# SYSCTRL_PADCONF_CORE register map
Vendor: Texas Instruments
Registers are 32-bit, access per field, reset 0x10F010F unless marked. A register's access mark holds for its fields unless they carry their own. Offsets are as the file gives them; [hi:lo] are bit positions; {n}, {i} and the like mark numbered series; 'fields as' and 'values as' point back to an identical list.

## SYSCTRL_PADCONF_CORE (part 4 of 10)
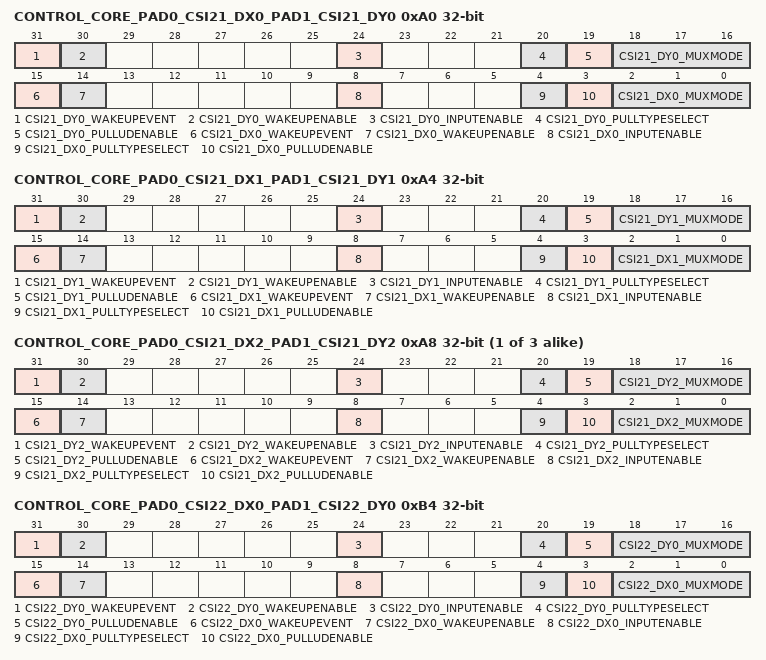
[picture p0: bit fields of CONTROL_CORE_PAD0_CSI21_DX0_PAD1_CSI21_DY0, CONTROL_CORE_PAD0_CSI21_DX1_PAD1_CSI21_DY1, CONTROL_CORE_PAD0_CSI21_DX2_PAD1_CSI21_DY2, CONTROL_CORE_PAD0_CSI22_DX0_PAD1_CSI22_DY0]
0xA0 CONTROL_CORE_PAD0_CSI21_DX0_PAD1_CSI21_DY0 — Register control for Pads csi21_dx0 and csi21_dy0 Access conditions. Read: unrestricted, Write: unrestricted
  [31] CSI21_DY0_WAKEUPEVENT ro — Pad_x wake-up event status latched in the IO
    0=CSI21_DY0_WAKEUPEVENT_0_r (No wake-up event occurred); 1=CSI21_DY0_WAKEUPEVENT_1_r (A wake-up event occurred)
  [30] CSI21_DY0_WAKEUPENABLE rw — Input pad wake-up enable (and OFF mode input enable value)
    0=wake-up detection is disabled; 1=wake-up detection is enabled
  [24] CSI21_DY0_INPUTENABLE rw — Input enable value for pad csi21_dy0
    0=Input buffer of I/O cell is disabled; 1=Input buffer of I/O cell is enabled
  [20] CSI21_DY0_PULLTYPESELECT rw — pullup/down selection for pad csi21_dy0
    0=pulldown selected; 1=pullup selected
  [19] CSI21_DY0_PULLUDENABLE rw — pullup/down enable for pad csi21_dy0
    0=pullup/down disabled; 1=pullup/down enabled
  [18:16] CSI21_DY0_MUXMODE rw — Functional multiplexing selection for pad csi21_dy0
    0=Select csi21_dy0; 3=Select gpi_68; 7=Select safe_mode
  [15] CSI21_DX0_WAKEUPEVENT ro — Pad_x wake-up event status latched in the IO
    0=CSI21_DX0_WAKEUPEVENT_0_r (No wake-up event occurred); 1=CSI21_DX0_WAKEUPEVENT_1_r (A wake-up event occurred)
  [14] CSI21_DX0_WAKEUPENABLE rw — Input pad wake-up enable (and OFF mode input enable value)
    values as CSI21_DY0_WAKEUPENABLE
  [8] CSI21_DX0_INPUTENABLE rw — Input enable value for pad csi21_dx0
    values as CSI21_DY0_INPUTENABLE
  [4] CSI21_DX0_PULLTYPESELECT rw — pullup/down selection for pad csi21_dx0
    0=pulldown selected; 1=pullup selected
  [3] CSI21_DX0_PULLUDENABLE rw — pullup/down enable for pad csi21_dx0
    0=pullup/down disabled; 1=pullup/down enabled
  [2:0] CSI21_DX0_MUXMODE rw — Functional multiplexing selection for pad csi21_dx0
    0=Select csi21_dx0; 3=Select gpi_67; 7=Select safe_mode
0xA4 CONTROL_CORE_PAD0_CSI21_DX1_PAD1_CSI21_DY1 — Register control for Pads csi21_dx1 and csi21_dy1 Access conditions. Read: unrestricted, Write: unrestricted
  [31] CSI21_DY1_WAKEUPEVENT ro — Pad_x wake-up event status latched in the IO
    0=CSI21_DY1_WAKEUPEVENT_0_r (No wake-up event occurred); 1=CSI21_DY1_WAKEUPEVENT_1_r (A wake-up event occurred)
  [30] CSI21_DY1_WAKEUPENABLE rw — Input pad wake-up enable (and OFF mode input enable value)
    values as CONTROL_CORE_PAD0_CSI21_DX0_PAD1_CSI21_DY0.CSI21_DY0_WAKEUPENABLE
  [24] CSI21_DY1_INPUTENABLE rw — Input enable value for pad csi21_dy1
    values as CONTROL_CORE_PAD0_CSI21_DX0_PAD1_CSI21_DY0.CSI21_DY0_INPUTENABLE
  [20] CSI21_DY1_PULLTYPESELECT rw — pullup/down selection for pad csi21_dy1
    0=pulldown selected; 1=pullup selected
  [19] CSI21_DY1_PULLUDENABLE rw — pullup/down enable for pad csi21_dy1
    0=pullup/down disabled; 1=pullup/down enabled
  [18:16] CSI21_DY1_MUXMODE rw — Functional multiplexing selection for pad csi21_dy1
    0=Select csi21_dy1; 3=Select gpi_70; 7=Select safe_mode
  [15] CSI21_DX1_WAKEUPEVENT ro — Pad_x wake-up event status latched in the IO
    0=CSI21_DX1_WAKEUPEVENT_0_r (No wake-up event occurred); 1=CSI21_DX1_WAKEUPEVENT_1_r (A wake-up event occurred)
  [14] CSI21_DX1_WAKEUPENABLE rw — Input pad wake-up enable (and OFF mode input enable value)
    values as CONTROL_CORE_PAD0_CSI21_DX0_PAD1_CSI21_DY0.CSI21_DY0_WAKEUPENABLE
  [8] CSI21_DX1_INPUTENABLE rw — Input enable value for pad csi21_dx1
    values as CONTROL_CORE_PAD0_CSI21_DX0_PAD1_CSI21_DY0.CSI21_DY0_INPUTENABLE
  [4] CSI21_DX1_PULLTYPESELECT rw — pullup/down selection for pad csi21_dx1
    0=pulldown selected; 1=pullup selected
  [3] CSI21_DX1_PULLUDENABLE rw — pullup/down enable for pad csi21_dx1
    0=pullup/down disabled; 1=pullup/down enabled
  [2:0] CSI21_DX1_MUXMODE rw — Functional multiplexing selection for pad csi21_dx1
    0=Select csi21_dx1; 3=Select gpi_69; 7=Select safe_mode
{0xA0+4i} CONTROL_CORE_PAD0_CSI21_DX{i}_PAD1_CSI21_DY{i} (i=2..4) — Register control for Pads csi21_dx{i} and csi21_dy{i} Access conditions. Read: unrestricted, Write: unrestricted
  [31] CSI21_DY{i}_WAKEUPEVENT ro — Pad_x wake-up event status latched in the IO
    0=CSI21_DY{i}_WAKEUPEVENT_0_r (No wake-up event occurred); 1=CSI21_DY{i}_WAKEUPEVENT_1_r (A wake-up event occurred)
  [30] CSI21_DY{i}_WAKEUPENABLE rw — Input pad wake-up enable (and OFF mode input enable value)
    values as CONTROL_CORE_PAD0_CSI21_DX0_PAD1_CSI21_DY0.CSI21_DY0_WAKEUPENABLE
  [24] CSI21_DY{i}_INPUTENABLE rw — Input enable value for pad csi21_dy{i}
    values as CONTROL_CORE_PAD0_CSI21_DX0_PAD1_CSI21_DY0.CSI21_DY0_INPUTENABLE
  [20] CSI21_DY{i}_PULLTYPESELECT rw — pullup/down selection for pad csi21_dy{i}
    0=pulldown selected; 1=pullup selected
  [19] CSI21_DY{i}_PULLUDENABLE rw — pullup/down enable for pad csi21_dy{i}
    0=pullup/down disabled; 1=pullup/down enabled
  [18:16] CSI21_DY{i}_MUXMODE rw — Functional multiplexing selection for pad csi21_dy{i}
    0=Select csi21_dy{i}; 3=Select gpi_{2i+68}; 7=Select safe_mode
  [15] CSI21_DX{i}_WAKEUPEVENT ro — Pad_x wake-up event status latched in the IO
    0=CSI21_DX{i}_WAKEUPEVENT_0_r (No wake-up event occurred); 1=CSI21_DX{i}_WAKEUPEVENT_1_r (A wake-up event occurred)
  [14] CSI21_DX{i}_WAKEUPENABLE rw — Input pad wake-up enable (and OFF mode input enable value)
    values as CONTROL_CORE_PAD0_CSI21_DX0_PAD1_CSI21_DY0.CSI21_DY0_WAKEUPENABLE
  [8] CSI21_DX{i}_INPUTENABLE rw — Input enable value for pad csi21_dx{i}
    values as CONTROL_CORE_PAD0_CSI21_DX0_PAD1_CSI21_DY0.CSI21_DY0_INPUTENABLE
  [4] CSI21_DX{i}_PULLTYPESELECT rw — pullup/down selection for pad csi21_dx{i}
    0=pulldown selected; 1=pullup selected
  [3] CSI21_DX{i}_PULLUDENABLE rw — pullup/down enable for pad csi21_dx{i}
    0=pullup/down disabled; 1=pullup/down enabled
  [2:0] CSI21_DX{i}_MUXMODE rw — Functional multiplexing selection for pad csi21_dx{i}
    0=Select csi21_dx{i}; 3=Select gpi_{2i+67}; 7=Select safe_mode
0xB4 CONTROL_CORE_PAD0_CSI22_DX0_PAD1_CSI22_DY0 — Register control for Pads csi22_dx0 and csi22_dy0 Access conditions. Read: unrestricted, Write: unrestricted
  [31] CSI22_DY0_WAKEUPEVENT ro — Pad_x wake-up event status latched in the IO
    0=CSI22_DY0_WAKEUPEVENT_0_r (No wake-up event occurred); 1=CSI22_DY0_WAKEUPEVENT_1_r (A wake-up event occurred)
  [30] CSI22_DY0_WAKEUPENABLE rw — Input pad wake-up enable (and OFF mode input enable value)
    values as CONTROL_CORE_PAD0_CSI21_DX0_PAD1_CSI21_DY0.CSI21_DY0_WAKEUPENABLE
  [24] CSI22_DY0_INPUTENABLE rw — Input enable value for pad csi22_dy0
    values as CONTROL_CORE_PAD0_CSI21_DX0_PAD1_CSI21_DY0.CSI21_DY0_INPUTENABLE
  [20] CSI22_DY0_PULLTYPESELECT rw — pullup/down selection for pad csi22_dy0
    0=pulldown selected; 1=pullup selected
  [19] CSI22_DY0_PULLUDENABLE rw — pullup/down enable for pad csi22_dy0
    0=pullup/down disabled; 1=pullup/down enabled
  [18:16] CSI22_DY0_MUXMODE rw — Functional multiplexing selection for pad csi22_dy0
    0=Select csi22_dy0; 3=Select gpi_78; 7=Select safe_mode
  [15] CSI22_DX0_WAKEUPEVENT ro — Pad_x wake-up event status latched in the IO
    0=CSI22_DX0_WAKEUPEVENT_0_r (No wake-up event occurred); 1=CSI22_DX0_WAKEUPEVENT_1_r (A wake-up event occurred)
  [14] CSI22_DX0_WAKEUPENABLE rw — Input pad wake-up enable (and OFF mode input enable value)
    values as CONTROL_CORE_PAD0_CSI21_DX0_PAD1_CSI21_DY0.CSI21_DY0_WAKEUPENABLE
  [8] CSI22_DX0_INPUTENABLE rw — Input enable value for pad csi22_dx0
    values as CONTROL_CORE_PAD0_CSI21_DX0_PAD1_CSI21_DY0.CSI21_DY0_INPUTENABLE
  [4] CSI22_DX0_PULLTYPESELECT rw — pullup/down selection for pad csi22_dx0
    0=pulldown selected; 1=pullup selected
  [3] CSI22_DX0_PULLUDENABLE rw — pullup/down enable for pad csi22_dx0
    0=pullup/down disabled; 1=pullup/down enabled
  [2:0] CSI22_DX0_MUXMODE rw — Functional multiplexing selection for pad csi22_dx0
    0=Select csi22_dx0; 3=Select gpi_77; 7=Select safe_mode
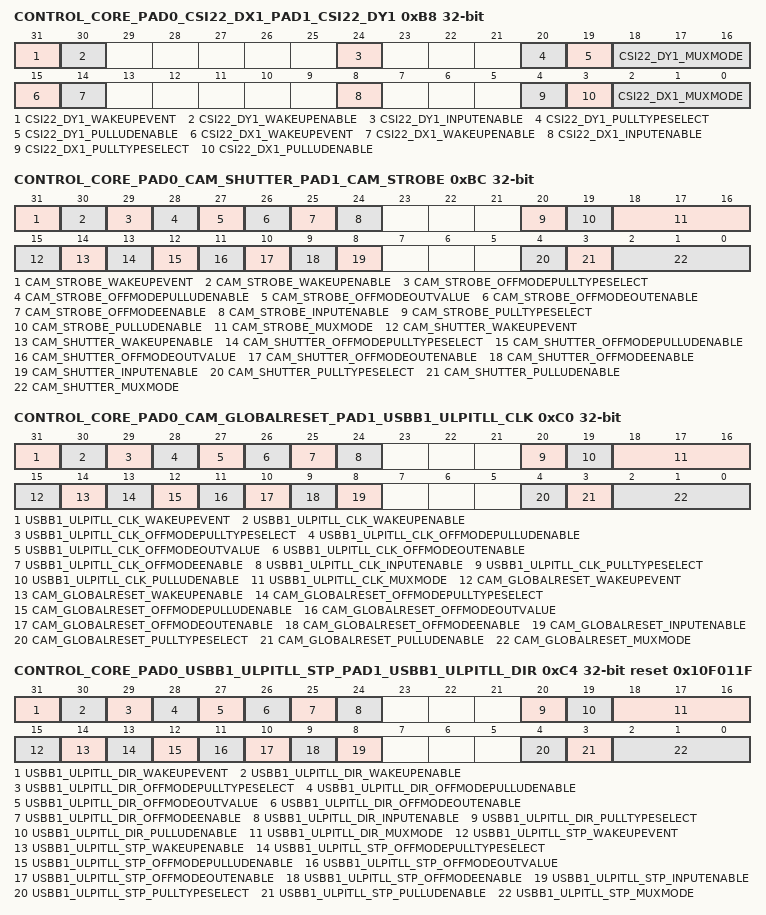
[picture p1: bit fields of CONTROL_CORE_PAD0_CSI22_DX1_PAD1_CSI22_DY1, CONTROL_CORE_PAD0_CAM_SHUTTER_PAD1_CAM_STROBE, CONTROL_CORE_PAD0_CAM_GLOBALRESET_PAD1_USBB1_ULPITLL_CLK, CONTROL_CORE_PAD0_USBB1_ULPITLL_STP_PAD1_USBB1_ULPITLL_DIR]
0xB8 CONTROL_CORE_PAD0_CSI22_DX1_PAD1_CSI22_DY1 — Register control for Pads csi22_dx1 and csi22_dy1 Access conditions. Read: unrestricted, Write: unrestricted
  [31] CSI22_DY1_WAKEUPEVENT ro — Pad_x wake-up event status latched in the IO
    0=CSI22_DY1_WAKEUPEVENT_0_r (No wake-up event occurred); 1=CSI22_DY1_WAKEUPEVENT_1_r (A wake-up event occurred)
  [30] CSI22_DY1_WAKEUPENABLE rw — Input pad wake-up enable (and OFF mode input enable value)
    values as CONTROL_CORE_PAD0_CSI21_DX0_PAD1_CSI21_DY0.CSI21_DY0_WAKEUPENABLE
  [24] CSI22_DY1_INPUTENABLE rw — Input enable value for pad csi22_dy1
    values as CONTROL_CORE_PAD0_CSI21_DX0_PAD1_CSI21_DY0.CSI21_DY0_INPUTENABLE
  [20] CSI22_DY1_PULLTYPESELECT rw — pullup/down selection for pad csi22_dy1
    0=pulldown selected; 1=pullup selected
  [19] CSI22_DY1_PULLUDENABLE rw — pullup/down enable for pad csi22_dy1
    0=pullup/down disabled; 1=pullup/down enabled
  [18:16] CSI22_DY1_MUXMODE rw — Functional multiplexing selection for pad csi22_dy1
    0=Select csi22_dy1; 3=Select gpi_80; 7=Select safe_mode
  [15] CSI22_DX1_WAKEUPEVENT ro — Pad_x wake-up event status latched in the IO
    0=CSI22_DX1_WAKEUPEVENT_0_r (No wake-up event occurred); 1=CSI22_DX1_WAKEUPEVENT_1_r (A wake-up event occurred)
  [14] CSI22_DX1_WAKEUPENABLE rw — Input pad wake-up enable (and OFF mode input enable value)
    values as CONTROL_CORE_PAD0_CSI21_DX0_PAD1_CSI21_DY0.CSI21_DY0_WAKEUPENABLE
  [8] CSI22_DX1_INPUTENABLE rw — Input enable value for pad csi22_dx1
    values as CONTROL_CORE_PAD0_CSI21_DX0_PAD1_CSI21_DY0.CSI21_DY0_INPUTENABLE
  [4] CSI22_DX1_PULLTYPESELECT rw — pullup/down selection for pad csi22_dx1
    0=pulldown selected; 1=pullup selected
  [3] CSI22_DX1_PULLUDENABLE rw — pullup/down enable for pad csi22_dx1
    0=pullup/down disabled; 1=pullup/down enabled
  [2:0] CSI22_DX1_MUXMODE rw — Functional multiplexing selection for pad csi22_dx1
    0=Select csi22_dx1; 3=Select gpi_79; 7=Select safe_mode
0xBC CONTROL_CORE_PAD0_CAM_SHUTTER_PAD1_CAM_STROBE — Register control for Pads cam_shutter and cam_strobe Access conditions. Read: unrestricted, Write: unrestricted
  [31] CAM_STROBE_WAKEUPEVENT ro — Pad_x wake-up event status latched in the IO
    0=CAM_STROBE_WAKEUPEVENT_0_r (No wake-up event occurred); 1=CAM_STROBE_WAKEUPEVENT_1_r (A wake-up event occurred)
  [30] CAM_STROBE_WAKEUPENABLE rw — Input pad wake-up enable (and OFF mode input enable value)
    values as CONTROL_CORE_PAD0_CSI21_DX0_PAD1_CSI21_DY0.CSI21_DY0_WAKEUPENABLE
  [29] CAM_STROBE_OFFMODEPULLTYPESELECT rw — OffMode mode pullup/down selection for pad cam_strobe
    0=Offmode pulldown selected; 1=Offmode pullup selected
  [28] CAM_STROBE_OFFMODEPULLUDENABLE rw — OffMode mode pullup/down enable for pad cam_strobe
    0=Offmode pullup/down disabled; 1=Offmode pullup/down enabled
  [27] CAM_STROBE_OFFMODEOUTVALUE rw — OffMode mode output value for pad cam_strobe
    0=Set value at 0; 1=Set value at 1
  [26] CAM_STROBE_OFFMODEOUTENABLE rw — OffMode mode output enable value for pad cam_strobe. This is an active low signal
    0=Output enable; 1=Output disable
  [25] CAM_STROBE_OFFMODEENABLE rw — OffMode mode override control for pad cam_strobe
    0=I/O state keeps its previous state when OFF mode is active; 1=I/O state is forced to OFF mode value when OFF mode is active
  [24] CAM_STROBE_INPUTENABLE rw — Input enable value for pad cam_strobe
    values as CONTROL_CORE_PAD0_CSI21_DX0_PAD1_CSI21_DY0.CSI21_DY0_INPUTENABLE
  [20] CAM_STROBE_PULLTYPESELECT rw — pullup/down selection for pad cam_strobe
    0=pulldown selected; 1=pullup selected
  [19] CAM_STROBE_PULLUDENABLE rw — pullup/down enable for pad cam_strobe
    0=pullup/down disabled; 1=pullup/down enabled
  [18:16] CAM_STROBE_MUXMODE rw — Functional multiplexing selection for pad cam_strobe
    0=Select cam_strobe; 3=Select gpio_82; 7=Select safe_mode
  [15] CAM_SHUTTER_WAKEUPEVENT ro — Pad_x wake-up event status latched in the IO
    0=CAM_SHUTTER_WAKEUPEVENT_0_r (No wake-up event occurred); 1=CAM_SHUTTER_WAKEUPEVENT_1_r (A wake-up event occurred)
  [14] CAM_SHUTTER_WAKEUPENABLE rw — Input pad wake-up enable (and OFF mode input enable value)
    values as CONTROL_CORE_PAD0_CSI21_DX0_PAD1_CSI21_DY0.CSI21_DY0_WAKEUPENABLE
  [13] CAM_SHUTTER_OFFMODEPULLTYPESELECT rw — OffMode mode pullup/down selection for pad cam_shutter
    0=Offmode pulldown selected; 1=Offmode pullup selected
  [12] CAM_SHUTTER_OFFMODEPULLUDENABLE rw — OffMode mode pullup/down enable for pad cam_shutter
    values as CAM_STROBE_OFFMODEPULLUDENABLE
  [11] CAM_SHUTTER_OFFMODEOUTVALUE rw — OffMode mode output value for pad cam_shutter
    0=Set value at 0; 1=Set value at 1
  [10] CAM_SHUTTER_OFFMODEOUTENABLE rw — OffMode mode output enable value for pad cam_shutter. This is an active low signal
    0=Output enable; 1=Output disable
  [9] CAM_SHUTTER_OFFMODEENABLE rw — OffMode mode override control for pad cam_shutter
    values as CAM_STROBE_OFFMODEENABLE
  [8] CAM_SHUTTER_INPUTENABLE rw — Input enable value for pad cam_shutter
    values as CONTROL_CORE_PAD0_CSI21_DX0_PAD1_CSI21_DY0.CSI21_DY0_INPUTENABLE
  [4] CAM_SHUTTER_PULLTYPESELECT rw — pullup/down selection for pad cam_shutter
    0=pulldown selected; 1=pullup selected
  [3] CAM_SHUTTER_PULLUDENABLE rw — pullup/down enable for pad cam_shutter
    0=pullup/down disabled; 1=pullup/down enabled
  [2:0] CAM_SHUTTER_MUXMODE rw — Functional multiplexing selection for pad cam_shutter
    0=Select cam_shutter; 3=Select gpio_81; 7=Select safe_mode
0xC0 CONTROL_CORE_PAD0_CAM_GLOBALRESET_PAD1_USBB1_ULPITLL_CLK — Register control for Pads cam_globalreset and usbb1_ulpitll_clk Access conditions. Read: unrestricted, Write: unrestricted
  [31] USBB1_ULPITLL_CLK_WAKEUPEVENT ro — Pad_x wake-up event status latched in the IO
    0=USBB1_ULPITLL_CLK_WAKEUPEVENT_0_r (No wake-up event occurred); 1=USBB1_ULPITLL_CLK_WAKEUPEVENT_1_r (A wake-up event occurred)
  [30] USBB1_ULPITLL_CLK_WAKEUPENABLE rw — Input pad wake-up enable (and OFF mode input enable value)
    values as CONTROL_CORE_PAD0_CSI21_DX0_PAD1_CSI21_DY0.CSI21_DY0_WAKEUPENABLE
  [29] USBB1_ULPITLL_CLK_OFFMODEPULLTYPESELECT rw — OffMode mode pullup/down selection for pad usbb1_ulpitll_clk
    0=Offmode pulldown selected; 1=Offmode pullup selected
  [28] USBB1_ULPITLL_CLK_OFFMODEPULLUDENABLE rw — OffMode mode pullup/down enable for pad usbb1_ulpitll_clk
    values as CONTROL_CORE_PAD0_CAM_SHUTTER_PAD1_CAM_STROBE.CAM_STROBE_OFFMODEPULLUDENABLE
  [27] USBB1_ULPITLL_CLK_OFFMODEOUTVALUE rw — OffMode mode output value for pad usbb1_ulpitll_clk
    0=Set value at 0; 1=Set value at 1
  [26] USBB1_ULPITLL_CLK_OFFMODEOUTENABLE rw — OffMode mode output enable value for pad usbb1_ulpitll_clk. This is an active low signal
    0=Output enable; 1=Output disable
  [25] USBB1_ULPITLL_CLK_OFFMODEENABLE rw — OffMode mode override control for pad usbb1_ulpitll_clk
    values as CONTROL_CORE_PAD0_CAM_SHUTTER_PAD1_CAM_STROBE.CAM_STROBE_OFFMODEENABLE
  [24] USBB1_ULPITLL_CLK_INPUTENABLE rw — Input enable value for pad usbb1_ulpitll_clk
    values as CONTROL_CORE_PAD0_CSI21_DX0_PAD1_CSI21_DY0.CSI21_DY0_INPUTENABLE
  [20] USBB1_ULPITLL_CLK_PULLTYPESELECT rw — pullup/down selection for pad usbb1_ulpitll_clk
    0=pulldown selected; 1=pullup selected
  [19] USBB1_ULPITLL_CLK_PULLUDENABLE rw — pullup/down enable for pad usbb1_ulpitll_clk
    0=pullup/down disabled; 1=pullup/down enabled
  [18:16] USBB1_ULPITLL_CLK_MUXMODE rw — Functional multiplexing selection for pad usbb1_ulpitll_clk
    0=Select usbb1_ulpitll_clk; 1=Select hsi1_cawake; 3=Select gpio_84; 4=Select usbb1_ulpiphy_clk; 6=Select hw_dbg20; 7=Select safe_mode
  [15] CAM_GLOBALRESET_WAKEUPEVENT ro — Pad_x wake-up event status latched in the IO
    0=CAM_GLOBALRESET_WAKEUPEVENT_0_r (No wake-up event occurred); 1=CAM_GLOBALRESET_WAKEUPEVENT_1_r (A wake-up event occurred)
  [14] CAM_GLOBALRESET_WAKEUPENABLE rw — Input pad wake-up enable (and OFF mode input enable value)
    values as CONTROL_CORE_PAD0_CSI21_DX0_PAD1_CSI21_DY0.CSI21_DY0_WAKEUPENABLE
  [13] CAM_GLOBALRESET_OFFMODEPULLTYPESELECT rw — OffMode mode pullup/down selection for pad cam_globalreset
    0=Offmode pulldown selected; 1=Offmode pullup selected
  [12] CAM_GLOBALRESET_OFFMODEPULLUDENABLE rw — OffMode mode pullup/down enable for pad cam_globalreset
    values as CONTROL_CORE_PAD0_CAM_SHUTTER_PAD1_CAM_STROBE.CAM_STROBE_OFFMODEPULLUDENABLE
  [11] CAM_GLOBALRESET_OFFMODEOUTVALUE rw — OffMode mode output value for pad cam_globalreset
    0=Set value at 0; 1=Set value at 1
  [10] CAM_GLOBALRESET_OFFMODEOUTENABLE rw — OffMode mode output enable value for pad cam_globalreset. This is an active low signal
    0=Output enable; 1=Output disable
  [9] CAM_GLOBALRESET_OFFMODEENABLE rw — OffMode mode override control for pad cam_globalreset
    values as CONTROL_CORE_PAD0_CAM_SHUTTER_PAD1_CAM_STROBE.CAM_STROBE_OFFMODEENABLE
  [8] CAM_GLOBALRESET_INPUTENABLE rw — Input enable value for pad cam_globalreset
    values as CONTROL_CORE_PAD0_CSI21_DX0_PAD1_CSI21_DY0.CSI21_DY0_INPUTENABLE
  [4] CAM_GLOBALRESET_PULLTYPESELECT rw — pullup/down selection for pad cam_globalreset
    0=pulldown selected; 1=pullup selected
  [3] CAM_GLOBALRESET_PULLUDENABLE rw — pullup/down enable for pad cam_globalreset
    0=pullup/down disabled; 1=pullup/down enabled
  [2:0] CAM_GLOBALRESET_MUXMODE rw — Functional multiplexing selection for pad cam_globalreset
    0=Select cam_globalreset; 3=Select gpio_83; 7=Select safe_mode
0xC4 CONTROL_CORE_PAD0_USBB1_ULPITLL_STP_PAD1_USBB1_ULPITLL_DIR reset 0x10F011F — Register control for Pads usbb1_ulpitll_stp and usbb1_ulpitll_dir Access conditions. Read: unrestricted, Write: unrestricted
  [31] USBB1_ULPITLL_DIR_WAKEUPEVENT ro — Pad_x wake-up event status latched in the IO
    0=USBB1_ULPITLL_DIR_WAKEUPEVENT_0_r (No wake-up event occurred); 1=USBB1_ULPITLL_DIR_WAKEUPEVENT_1_r (A wake-up event occurred)
  [30] USBB1_ULPITLL_DIR_WAKEUPENABLE rw — Input pad wake-up enable (and OFF mode input enable value)
    values as CONTROL_CORE_PAD0_CSI21_DX0_PAD1_CSI21_DY0.CSI21_DY0_WAKEUPENABLE
  [29] USBB1_ULPITLL_DIR_OFFMODEPULLTYPESELECT rw — OffMode mode pullup/down selection for pad usbb1_ulpitll_dir
    0=Offmode pulldown selected; 1=Offmode pullup selected
  [28] USBB1_ULPITLL_DIR_OFFMODEPULLUDENABLE rw — OffMode mode pullup/down enable for pad usbb1_ulpitll_dir
    values as CONTROL_CORE_PAD0_CAM_SHUTTER_PAD1_CAM_STROBE.CAM_STROBE_OFFMODEPULLUDENABLE
  [27] USBB1_ULPITLL_DIR_OFFMODEOUTVALUE rw — OffMode mode output value for pad usbb1_ulpitll_dir
    0=Set value at 0; 1=Set value at 1
  [26] USBB1_ULPITLL_DIR_OFFMODEOUTENABLE rw — OffMode mode output enable value for pad usbb1_ulpitll_dir. This is an active low signal
    0=Output enable; 1=Output disable
  [25] USBB1_ULPITLL_DIR_OFFMODEENABLE rw — OffMode mode override control for pad usbb1_ulpitll_dir
    values as CONTROL_CORE_PAD0_CAM_SHUTTER_PAD1_CAM_STROBE.CAM_STROBE_OFFMODEENABLE
  [24] USBB1_ULPITLL_DIR_INPUTENABLE rw — Input enable value for pad usbb1_ulpitll_dir
    values as CONTROL_CORE_PAD0_CSI21_DX0_PAD1_CSI21_DY0.CSI21_DY0_INPUTENABLE
  [20] USBB1_ULPITLL_DIR_PULLTYPESELECT rw — pullup/down selection for pad usbb1_ulpitll_dir
    0=pulldown selected; 1=pullup selected
  [19] USBB1_ULPITLL_DIR_PULLUDENABLE rw — pullup/down enable for pad usbb1_ulpitll_dir
    0=pullup/down disabled; 1=pullup/down enabled
  [18:16] USBB1_ULPITLL_DIR_MUXMODE rw — Functional multiplexing selection for pad usbb1_ulpitll_dir
    0=Select usbb1_ulpitll_dir; 1=Select hsi1_caflag; 2=Select mcbsp4_fsr; 3=Select gpio_86; 4=Select usbb1_ulpiphy_dir; 6=Select hw_dbg22; 7=Select safe_mode
  [15] USBB1_ULPITLL_STP_WAKEUPEVENT ro — Pad_x wake-up event status latched in the IO
    0=USBB1_ULPITLL_STP_WAKEUPEVENT_0_r (No wake-up event occurred); 1=USBB1_ULPITLL_STP_WAKEUPEVENT_1_r (A wake-up event occurred)
  [14] USBB1_ULPITLL_STP_WAKEUPENABLE rw — Input pad wake-up enable (and OFF mode input enable value)
    values as CONTROL_CORE_PAD0_CSI21_DX0_PAD1_CSI21_DY0.CSI21_DY0_WAKEUPENABLE
  [13] USBB1_ULPITLL_STP_OFFMODEPULLTYPESELECT rw — OffMode mode pullup/down selection for pad usbb1_ulpitll_stp
    0=Offmode pulldown selected; 1=Offmode pullup selected
  [12] USBB1_ULPITLL_STP_OFFMODEPULLUDENABLE rw — OffMode mode pullup/down enable for pad usbb1_ulpitll_stp
    values as CONTROL_CORE_PAD0_CAM_SHUTTER_PAD1_CAM_STROBE.CAM_STROBE_OFFMODEPULLUDENABLE
  [11] USBB1_ULPITLL_STP_OFFMODEOUTVALUE rw — OffMode mode output value for pad usbb1_ulpitll_stp
    0=Set value at 0; 1=Set value at 1
  [10] USBB1_ULPITLL_STP_OFFMODEOUTENABLE rw — OffMode mode output enable value for pad usbb1_ulpitll_stp. This is an active low signal
    0=Output enable; 1=Output disable
  [9] USBB1_ULPITLL_STP_OFFMODEENABLE rw — OffMode mode override control for pad usbb1_ulpitll_stp
    values as CONTROL_CORE_PAD0_CAM_SHUTTER_PAD1_CAM_STROBE.CAM_STROBE_OFFMODEENABLE
  [8] USBB1_ULPITLL_STP_INPUTENABLE rw — Input enable value for pad usbb1_ulpitll_stp
    values as CONTROL_CORE_PAD0_CSI21_DX0_PAD1_CSI21_DY0.CSI21_DY0_INPUTENABLE
  [4] USBB1_ULPITLL_STP_PULLTYPESELECT rw — pullup/down selection for pad usbb1_ulpitll_stp
    0=pulldown selected; 1=pullup selected
  [3] USBB1_ULPITLL_STP_PULLUDENABLE rw — pullup/down enable for pad usbb1_ulpitll_stp
    0=pullup/down disabled; 1=pullup/down enabled
  [2:0] USBB1_ULPITLL_STP_MUXMODE rw — Functional multiplexing selection for pad usbb1_ulpitll_stp
    0=Select usbb1_ulpitll_stp; 1=Select hsi1_cadata; 2=Select mcbsp4_clkr; 3=Select gpio_85; 4=Select usbb1_ulpiphy_stp; 5=Select usbb1_mm_rxdp; 6=Select hw_dbg21; 7=Select safe_mode
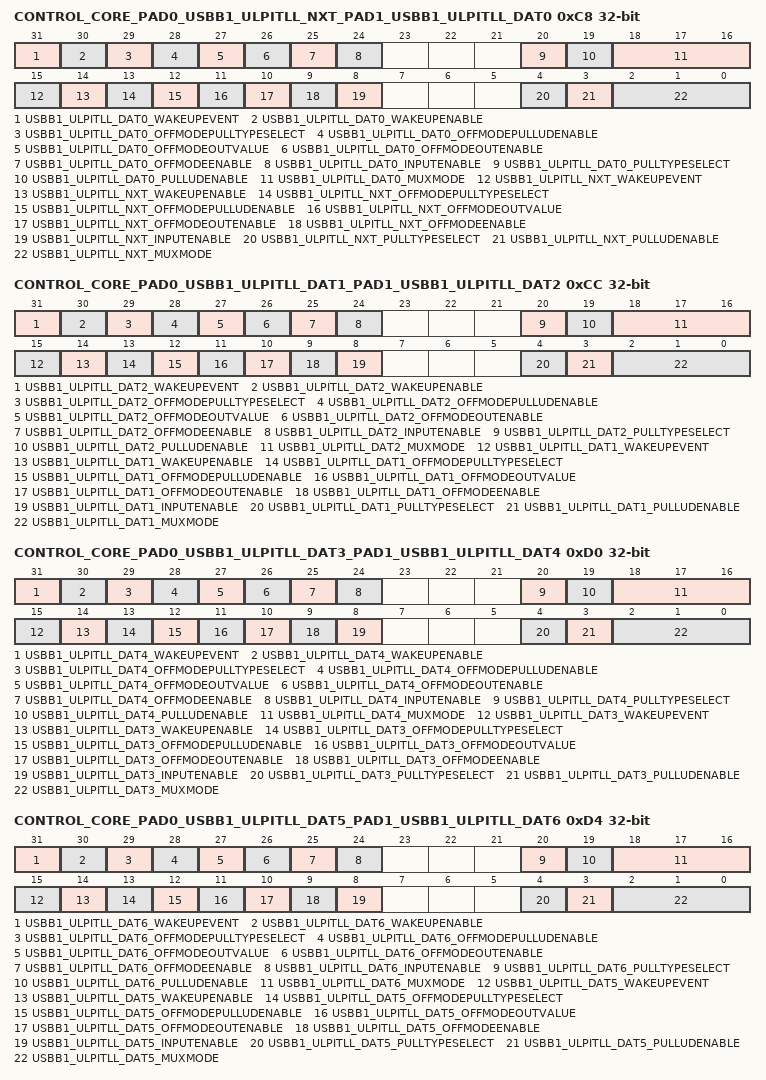
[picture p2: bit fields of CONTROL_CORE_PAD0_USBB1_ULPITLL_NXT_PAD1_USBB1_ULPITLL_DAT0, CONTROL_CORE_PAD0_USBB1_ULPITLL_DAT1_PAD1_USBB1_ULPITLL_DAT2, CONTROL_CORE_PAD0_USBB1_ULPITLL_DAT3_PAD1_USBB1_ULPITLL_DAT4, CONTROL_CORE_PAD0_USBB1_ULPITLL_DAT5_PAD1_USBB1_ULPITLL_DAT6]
0xC8 CONTROL_CORE_PAD0_USBB1_ULPITLL_NXT_PAD1_USBB1_ULPITLL_DAT0 — Register control for Pads usbb1_ulpitll_nxt and usbb1_ulpitll_dat0 Access conditions. Read: unrestricted, Write: unrestricted
  [31] USBB1_ULPITLL_DAT0_WAKEUPEVENT ro — Pad_x wake-up event status latched in the IO
    0=USBB1_ULPITLL_DAT0_WAKEUPEVENT_0_r (No wake-up event occurred); 1=USBB1_ULPITLL_DAT0_WAKEUPEVENT_1_r (A wake-up event occurred)
  [30] USBB1_ULPITLL_DAT0_WAKEUPENABLE rw — Input pad wake-up enable (and OFF mode input enable value)
    values as CONTROL_CORE_PAD0_CSI21_DX0_PAD1_CSI21_DY0.CSI21_DY0_WAKEUPENABLE
  [29] USBB1_ULPITLL_DAT0_OFFMODEPULLTYPESELECT rw — OffMode mode pullup/down selection for pad usbb1_ulpitll_dat0
    0=Offmode pulldown selected; 1=Offmode pullup selected
  [28] USBB1_ULPITLL_DAT0_OFFMODEPULLUDENABLE rw — OffMode mode pullup/down enable for pad usbb1_ulpitll_dat0
    values as CONTROL_CORE_PAD0_CAM_SHUTTER_PAD1_CAM_STROBE.CAM_STROBE_OFFMODEPULLUDENABLE
  [27] USBB1_ULPITLL_DAT0_OFFMODEOUTVALUE rw — OffMode mode output value for pad usbb1_ulpitll_dat0
    0=Set value at 0; 1=Set value at 1
  [26] USBB1_ULPITLL_DAT0_OFFMODEOUTENABLE rw — OffMode mode output enable value for pad usbb1_ulpitll_dat0. This is an active low signal
    0=Output enable; 1=Output disable
  [25] USBB1_ULPITLL_DAT0_OFFMODEENABLE rw — OffMode mode override control for pad usbb1_ulpitll_dat0
    values as CONTROL_CORE_PAD0_CAM_SHUTTER_PAD1_CAM_STROBE.CAM_STROBE_OFFMODEENABLE
  [24] USBB1_ULPITLL_DAT0_INPUTENABLE rw — Input enable value for pad usbb1_ulpitll_dat0
    values as CONTROL_CORE_PAD0_CSI21_DX0_PAD1_CSI21_DY0.CSI21_DY0_INPUTENABLE
  [20] USBB1_ULPITLL_DAT0_PULLTYPESELECT rw — pullup/down selection for pad usbb1_ulpitll_dat0
    0=pulldown selected; 1=pullup selected
  [19] USBB1_ULPITLL_DAT0_PULLUDENABLE rw — pullup/down enable for pad usbb1_ulpitll_dat0
    0=pullup/down disabled; 1=pullup/down enabled
  [18:16] USBB1_ULPITLL_DAT0_MUXMODE rw — Functional multiplexing selection for pad usbb1_ulpitll_dat0
    0=Select usbb1_ulpitll_dat0; 1=Select hsi1_acwake; 2=Select mcbsp4_clkx; 3=Select gpio_88; 4=Select usbb1_ulpiphy_dat0; 5=Select usbb1_mm_txen; 6=Select hw_dbg24; 7=Select safe_mode
  [15] USBB1_ULPITLL_NXT_WAKEUPEVENT ro — Pad_x wake-up event status latched in the IO
    0=USBB1_ULPITLL_NXT_WAKEUPEVENT_0_r (No wake-up event occurred); 1=USBB1_ULPITLL_NXT_WAKEUPEVENT_1_r (A wake-up event occurred)
  [14] USBB1_ULPITLL_NXT_WAKEUPENABLE rw — Input pad wake-up enable (and OFF mode input enable value)
    values as CONTROL_CORE_PAD0_CSI21_DX0_PAD1_CSI21_DY0.CSI21_DY0_WAKEUPENABLE
  [13] USBB1_ULPITLL_NXT_OFFMODEPULLTYPESELECT rw — OffMode mode pullup/down selection for pad usbb1_ulpitll_nxt
    0=Offmode pulldown selected; 1=Offmode pullup selected
  [12] USBB1_ULPITLL_NXT_OFFMODEPULLUDENABLE rw — OffMode mode pullup/down enable for pad usbb1_ulpitll_nxt
    values as CONTROL_CORE_PAD0_CAM_SHUTTER_PAD1_CAM_STROBE.CAM_STROBE_OFFMODEPULLUDENABLE
  [11] USBB1_ULPITLL_NXT_OFFMODEOUTVALUE rw — OffMode mode output value for pad usbb1_ulpitll_nxt
    0=Set value at 0; 1=Set value at 1
  [10] USBB1_ULPITLL_NXT_OFFMODEOUTENABLE rw — OffMode mode output enable value for pad usbb1_ulpitll_nxt. This is an active low signal
    0=Output enable; 1=Output disable
  [9] USBB1_ULPITLL_NXT_OFFMODEENABLE rw — OffMode mode override control for pad usbb1_ulpitll_nxt
    values as CONTROL_CORE_PAD0_CAM_SHUTTER_PAD1_CAM_STROBE.CAM_STROBE_OFFMODEENABLE
  [8] USBB1_ULPITLL_NXT_INPUTENABLE rw — Input enable value for pad usbb1_ulpitll_nxt
    values as CONTROL_CORE_PAD0_CSI21_DX0_PAD1_CSI21_DY0.CSI21_DY0_INPUTENABLE
  [4] USBB1_ULPITLL_NXT_PULLTYPESELECT rw — pullup/down selection for pad usbb1_ulpitll_nxt
    0=pulldown selected; 1=pullup selected
  [3] USBB1_ULPITLL_NXT_PULLUDENABLE rw — pullup/down enable for pad usbb1_ulpitll_nxt
    0=pullup/down disabled; 1=pullup/down enabled
  [2:0] USBB1_ULPITLL_NXT_MUXMODE rw — Functional multiplexing selection for pad usbb1_ulpitll_nxt
    0=Select usbb1_ulpitll_nxt; 1=Select hsi1_acready; 2=Select mcbsp4_fsx; 3=Select gpio_87; 4=Select usbb1_ulpiphy_nxt; 5=Select usbb1_mm_rxdm; 6=Select hw_dbg23; 7=Select safe_mode
0xCC CONTROL_CORE_PAD0_USBB1_ULPITLL_DAT1_PAD1_USBB1_ULPITLL_DAT2 — Register control for Pads usbb1_ulpitll_dat1 and usbb1_ulpitll_dat2 Access conditions. Read: unrestricted, Write: unrestricted
  [31] USBB1_ULPITLL_DAT2_WAKEUPEVENT ro — Pad_x wake-up event status latched in the IO
    0=USBB1_ULPITLL_DAT2_WAKEUPEVENT_0_r (No wake-up event occurred); 1=USBB1_ULPITLL_DAT2_WAKEUPEVENT_1_r (A wake-up event occurred)
  [30] USBB1_ULPITLL_DAT2_WAKEUPENABLE rw — Input pad wake-up enable (and OFF mode input enable value)
    values as CONTROL_CORE_PAD0_CSI21_DX0_PAD1_CSI21_DY0.CSI21_DY0_WAKEUPENABLE
  [29] USBB1_ULPITLL_DAT2_OFFMODEPULLTYPESELECT rw — OffMode mode pullup/down selection for pad usbb1_ulpitll_dat2
    0=Offmode pulldown selected; 1=Offmode pullup selected
  [28] USBB1_ULPITLL_DAT2_OFFMODEPULLUDENABLE rw — OffMode mode pullup/down enable for pad usbb1_ulpitll_dat2
    values as CONTROL_CORE_PAD0_CAM_SHUTTER_PAD1_CAM_STROBE.CAM_STROBE_OFFMODEPULLUDENABLE
  [27] USBB1_ULPITLL_DAT2_OFFMODEOUTVALUE rw — OffMode mode output value for pad usbb1_ulpitll_dat2
    0=Set value at 0; 1=Set value at 1
  [26] USBB1_ULPITLL_DAT2_OFFMODEOUTENABLE rw — OffMode mode output enable value for pad usbb1_ulpitll_dat2. This is an active low signal
    0=Output enable; 1=Output disable
  [25] USBB1_ULPITLL_DAT2_OFFMODEENABLE rw — OffMode mode override control for pad usbb1_ulpitll_dat2
    values as CONTROL_CORE_PAD0_CAM_SHUTTER_PAD1_CAM_STROBE.CAM_STROBE_OFFMODEENABLE
  [24] USBB1_ULPITLL_DAT2_INPUTENABLE rw — Input enable value for pad usbb1_ulpitll_dat2
    values as CONTROL_CORE_PAD0_CSI21_DX0_PAD1_CSI21_DY0.CSI21_DY0_INPUTENABLE
  [20] USBB1_ULPITLL_DAT2_PULLTYPESELECT rw — pullup/down selection for pad usbb1_ulpitll_dat2
    0=pulldown selected; 1=pullup selected
  [19] USBB1_ULPITLL_DAT2_PULLUDENABLE rw — pullup/down enable for pad usbb1_ulpitll_dat2
    0=pullup/down disabled; 1=pullup/down enabled
  [18:16] USBB1_ULPITLL_DAT2_MUXMODE rw — Functional multiplexing selection for pad usbb1_ulpitll_dat2
    0=Select usbb1_ulpitll_dat2; 1=Select hsi1_acflag; 2=Select mcbsp4_dr; 3=Select gpio_90; 4=Select usbb1_ulpiphy_dat2; 5=Select usbb1_mm_txse0; 6=Select hw_dbg26; 7=Select safe_mode
  [15] USBB1_ULPITLL_DAT1_WAKEUPEVENT ro — Pad_x wake-up event status latched in the IO
    0=USBB1_ULPITLL_DAT1_WAKEUPEVENT_0_r (No wake-up event occurred); 1=USBB1_ULPITLL_DAT1_WAKEUPEVENT_1_r (A wake-up event occurred)
  [14] USBB1_ULPITLL_DAT1_WAKEUPENABLE rw — Input pad wake-up enable (and OFF mode input enable value)
    values as CONTROL_CORE_PAD0_CSI21_DX0_PAD1_CSI21_DY0.CSI21_DY0_WAKEUPENABLE
  [13] USBB1_ULPITLL_DAT1_OFFMODEPULLTYPESELECT rw — OffMode mode pullup/down selection for pad usbb1_ulpitll_dat1
    0=Offmode pulldown selected; 1=Offmode pullup selected
  [12] USBB1_ULPITLL_DAT1_OFFMODEPULLUDENABLE rw — OffMode mode pullup/down enable for pad usbb1_ulpitll_dat1
    values as CONTROL_CORE_PAD0_CAM_SHUTTER_PAD1_CAM_STROBE.CAM_STROBE_OFFMODEPULLUDENABLE
  [11] USBB1_ULPITLL_DAT1_OFFMODEOUTVALUE rw — OffMode mode output value for pad usbb1_ulpitll_dat1
    0=Set value at 0; 1=Set value at 1
  [10] USBB1_ULPITLL_DAT1_OFFMODEOUTENABLE rw — OffMode mode output enable value for pad usbb1_ulpitll_dat1. This is an active low signal
    0=Output enable; 1=Output disable
  [9] USBB1_ULPITLL_DAT1_OFFMODEENABLE rw — OffMode mode override control for pad usbb1_ulpitll_dat1
    values as CONTROL_CORE_PAD0_CAM_SHUTTER_PAD1_CAM_STROBE.CAM_STROBE_OFFMODEENABLE
  [8] USBB1_ULPITLL_DAT1_INPUTENABLE rw — Input enable value for pad usbb1_ulpitll_dat1
    values as CONTROL_CORE_PAD0_CSI21_DX0_PAD1_CSI21_DY0.CSI21_DY0_INPUTENABLE
  [4] USBB1_ULPITLL_DAT1_PULLTYPESELECT rw — pullup/down selection for pad usbb1_ulpitll_dat1
    0=pulldown selected; 1=pullup selected
  [3] USBB1_ULPITLL_DAT1_PULLUDENABLE rw — pullup/down enable for pad usbb1_ulpitll_dat1
    0=pullup/down disabled; 1=pullup/down enabled
  [2:0] USBB1_ULPITLL_DAT1_MUXMODE rw — Functional multiplexing selection for pad usbb1_ulpitll_dat1
    0=Select usbb1_ulpitll_dat1; 1=Select hsi1_acdata; 2=Select mcbsp4_dx; 3=Select gpio_89; 4=Select usbb1_ulpiphy_dat1; 5=Select usbb1_mm_txdat; 6=Select hw_dbg25; 7=Select safe_mode
0xD0 CONTROL_CORE_PAD0_USBB1_ULPITLL_DAT3_PAD1_USBB1_ULPITLL_DAT4 — Register control for Pads usbb1_ulpitll_dat3 and usbb1_ulpitll_dat4 Access conditions. Read: unrestricted, Write: unrestricted
  [31] USBB1_ULPITLL_DAT4_WAKEUPEVENT ro — Pad_x wake-up event status latched in the IO
    0=USBB1_ULPITLL_DAT4_WAKEUPEVENT_0_r (No wake-up event occurred); 1=USBB1_ULPITLL_DAT4_WAKEUPEVENT_1_r (A wake-up event occurred)
  [30] USBB1_ULPITLL_DAT4_WAKEUPENABLE rw — Input pad wake-up enable (and OFF mode input enable value)
    values as CONTROL_CORE_PAD0_CSI21_DX0_PAD1_CSI21_DY0.CSI21_DY0_WAKEUPENABLE
  [29] USBB1_ULPITLL_DAT4_OFFMODEPULLTYPESELECT rw — OffMode mode pullup/down selection for pad usbb1_ulpitll_dat4
    0=Offmode pulldown selected; 1=Offmode pullup selected
  [28] USBB1_ULPITLL_DAT4_OFFMODEPULLUDENABLE rw — OffMode mode pullup/down enable for pad usbb1_ulpitll_dat4
    values as CONTROL_CORE_PAD0_CAM_SHUTTER_PAD1_CAM_STROBE.CAM_STROBE_OFFMODEPULLUDENABLE
  [27] USBB1_ULPITLL_DAT4_OFFMODEOUTVALUE rw — OffMode mode output value for pad usbb1_ulpitll_dat4
    0=Set value at 0; 1=Set value at 1
  [26] USBB1_ULPITLL_DAT4_OFFMODEOUTENABLE rw — OffMode mode output enable value for pad usbb1_ulpitll_dat4. This is an active low signal
    0=Output enable; 1=Output disable
  [25] USBB1_ULPITLL_DAT4_OFFMODEENABLE rw — OffMode mode override control for pad usbb1_ulpitll_dat4
    values as CONTROL_CORE_PAD0_CAM_SHUTTER_PAD1_CAM_STROBE.CAM_STROBE_OFFMODEENABLE
  [24] USBB1_ULPITLL_DAT4_INPUTENABLE rw — Input enable value for pad usbb1_ulpitll_dat4
    values as CONTROL_CORE_PAD0_CSI21_DX0_PAD1_CSI21_DY0.CSI21_DY0_INPUTENABLE
  [20] USBB1_ULPITLL_DAT4_PULLTYPESELECT rw — pullup/down selection for pad usbb1_ulpitll_dat4
    0=pulldown selected; 1=pullup selected
  [19] USBB1_ULPITLL_DAT4_PULLUDENABLE rw — pullup/down enable for pad usbb1_ulpitll_dat4
    0=pullup/down disabled; 1=pullup/down enabled
  [18:16] USBB1_ULPITLL_DAT4_MUXMODE rw — Functional multiplexing selection for pad usbb1_ulpitll_dat4
    0=Select usbb1_ulpitll_dat4; 1=Select dmtimer8_pwm_evt; 2=Select abe_mcbsp3_dr; 3=Select gpio_92; 4=Select usbb1_ulpiphy_dat4; 6=Select hw_dbg28; 7=Select safe_mode
  [15] USBB1_ULPITLL_DAT3_WAKEUPEVENT ro — Pad_x wake-up event status latched in the IO
    0=USBB1_ULPITLL_DAT3_WAKEUPEVENT_0_r (No wake-up event occurred); 1=USBB1_ULPITLL_DAT3_WAKEUPEVENT_1_r (A wake-up event occurred)
  [14] USBB1_ULPITLL_DAT3_WAKEUPENABLE rw — Input pad wake-up enable (and OFF mode input enable value)
    values as CONTROL_CORE_PAD0_CSI21_DX0_PAD1_CSI21_DY0.CSI21_DY0_WAKEUPENABLE
  [13] USBB1_ULPITLL_DAT3_OFFMODEPULLTYPESELECT rw — OffMode mode pullup/down selection for pad usbb1_ulpitll_dat3
    0=Offmode pulldown selected; 1=Offmode pullup selected
  [12] USBB1_ULPITLL_DAT3_OFFMODEPULLUDENABLE rw — OffMode mode pullup/down enable for pad usbb1_ulpitll_dat3
    values as CONTROL_CORE_PAD0_CAM_SHUTTER_PAD1_CAM_STROBE.CAM_STROBE_OFFMODEPULLUDENABLE
  [11] USBB1_ULPITLL_DAT3_OFFMODEOUTVALUE rw — OffMode mode output value for pad usbb1_ulpitll_dat3
    0=Set value at 0; 1=Set value at 1
  [10] USBB1_ULPITLL_DAT3_OFFMODEOUTENABLE rw — OffMode mode output enable value for pad usbb1_ulpitll_dat3. This is an active low signal
    0=Output enable; 1=Output disable
  [9] USBB1_ULPITLL_DAT3_OFFMODEENABLE rw — OffMode mode override control for pad usbb1_ulpitll_dat3
    values as CONTROL_CORE_PAD0_CAM_SHUTTER_PAD1_CAM_STROBE.CAM_STROBE_OFFMODEENABLE
  [8] USBB1_ULPITLL_DAT3_INPUTENABLE rw — Input enable value for pad usbb1_ulpitll_dat3
    values as CONTROL_CORE_PAD0_CSI21_DX0_PAD1_CSI21_DY0.CSI21_DY0_INPUTENABLE
  [4] USBB1_ULPITLL_DAT3_PULLTYPESELECT rw — pullup/down selection for pad usbb1_ulpitll_dat3
    0=pulldown selected; 1=pullup selected
  [3] USBB1_ULPITLL_DAT3_PULLUDENABLE rw — pullup/down enable for pad usbb1_ulpitll_dat3
    0=pullup/down disabled; 1=pullup/down enabled
  [2:0] USBB1_ULPITLL_DAT3_MUXMODE rw — Functional multiplexing selection for pad usbb1_ulpitll_dat3
    0=Select usbb1_ulpitll_dat3; 1=Select hsi1_caready; 3=Select gpio_91; 4=Select usbb1_ulpiphy_dat3; 5=Select usbb1_mm_rxrcv; 6=Select hw_dbg27; 7=Select safe_mode
0xD4 CONTROL_CORE_PAD0_USBB1_ULPITLL_DAT5_PAD1_USBB1_ULPITLL_DAT6 — Register control for Pads usbb1_ulpitll_dat5 and usbb1_ulpitll_dat6 Access conditions. Read: unrestricted, Write: unrestricted
  [31] USBB1_ULPITLL_DAT6_WAKEUPEVENT ro — Pad_x wake-up event status latched in the IO
    0=USBB1_ULPITLL_DAT6_WAKEUPEVENT_0_r (No wake-up event occurred); 1=USBB1_ULPITLL_DAT6_WAKEUPEVENT_1_r (A wake-up event occurred)
  [30] USBB1_ULPITLL_DAT6_WAKEUPENABLE rw — Input pad wake-up enable (and OFF mode input enable value)
    values as CONTROL_CORE_PAD0_CSI21_DX0_PAD1_CSI21_DY0.CSI21_DY0_WAKEUPENABLE
  [29] USBB1_ULPITLL_DAT6_OFFMODEPULLTYPESELECT rw — OffMode mode pullup/down selection for pad usbb1_ulpitll_dat6
    0=Offmode pulldown selected; 1=Offmode pullup selected
  [28] USBB1_ULPITLL_DAT6_OFFMODEPULLUDENABLE rw — OffMode mode pullup/down enable for pad usbb1_ulpitll_dat6
    values as CONTROL_CORE_PAD0_CAM_SHUTTER_PAD1_CAM_STROBE.CAM_STROBE_OFFMODEPULLUDENABLE
  [27] USBB1_ULPITLL_DAT6_OFFMODEOUTVALUE rw — OffMode mode output value for pad usbb1_ulpitll_dat6
    0=Set value at 0; 1=Set value at 1
  [26] USBB1_ULPITLL_DAT6_OFFMODEOUTENABLE rw — OffMode mode output enable value for pad usbb1_ulpitll_dat6. This is an active low signal
    0=Output enable; 1=Output disable
  [25] USBB1_ULPITLL_DAT6_OFFMODEENABLE rw — OffMode mode override control for pad usbb1_ulpitll_dat6
    values as CONTROL_CORE_PAD0_CAM_SHUTTER_PAD1_CAM_STROBE.CAM_STROBE_OFFMODEENABLE
  [24] USBB1_ULPITLL_DAT6_INPUTENABLE rw — Input enable value for pad usbb1_ulpitll_dat6
    values as CONTROL_CORE_PAD0_CSI21_DX0_PAD1_CSI21_DY0.CSI21_DY0_INPUTENABLE
  [20] USBB1_ULPITLL_DAT6_PULLTYPESELECT rw — pullup/down selection for pad usbb1_ulpitll_dat6
    0=pulldown selected; 1=pullup selected
  [19] USBB1_ULPITLL_DAT6_PULLUDENABLE rw — pullup/down enable for pad usbb1_ulpitll_dat6
    0=pullup/down disabled; 1=pullup/down enabled
  [18:16] USBB1_ULPITLL_DAT6_MUXMODE rw — Functional multiplexing selection for pad usbb1_ulpitll_dat6
    0=Select usbb1_ulpitll_dat6; 1=Select dmtimer10_pwm_evt; 2=Select abe_mcbsp3_clkx; 3=Select gpio_94; 4=Select usbb1_ulpiphy_dat6; 5=Select abe_dmic_din3; 6=Select hw_dbg30; 7=Select safe_mode
  [15] USBB1_ULPITLL_DAT5_WAKEUPEVENT ro — Pad_x wake-up event status latched in the IO
    0=USBB1_ULPITLL_DAT5_WAKEUPEVENT_0_r (No wake-up event occurred); 1=USBB1_ULPITLL_DAT5_WAKEUPEVENT_1_r (A wake-up event occurred)
  [14] USBB1_ULPITLL_DAT5_WAKEUPENABLE rw — Input pad wake-up enable (and OFF mode input enable value)
    values as CONTROL_CORE_PAD0_CSI21_DX0_PAD1_CSI21_DY0.CSI21_DY0_WAKEUPENABLE
  [13] USBB1_ULPITLL_DAT5_OFFMODEPULLTYPESELECT rw — OffMode mode pullup/down selection for pad usbb1_ulpitll_dat5
    0=Offmode pulldown selected; 1=Offmode pullup selected
  [12] USBB1_ULPITLL_DAT5_OFFMODEPULLUDENABLE rw — OffMode mode pullup/down enable for pad usbb1_ulpitll_dat5
    values as CONTROL_CORE_PAD0_CAM_SHUTTER_PAD1_CAM_STROBE.CAM_STROBE_OFFMODEPULLUDENABLE
  [11] USBB1_ULPITLL_DAT5_OFFMODEOUTVALUE rw — OffMode mode output value for pad usbb1_ulpitll_dat5
    0=Set value at 0; 1=Set value at 1
  [10] USBB1_ULPITLL_DAT5_OFFMODEOUTENABLE rw — OffMode mode output enable value for pad usbb1_ulpitll_dat5. This is an active low signal
    0=Output enable; 1=Output disable
  [9] USBB1_ULPITLL_DAT5_OFFMODEENABLE rw — OffMode mode override control for pad usbb1_ulpitll_dat5
    values as CONTROL_CORE_PAD0_CAM_SHUTTER_PAD1_CAM_STROBE.CAM_STROBE_OFFMODEENABLE
  [8] USBB1_ULPITLL_DAT5_INPUTENABLE rw — Input enable value for pad usbb1_ulpitll_dat5
    values as CONTROL_CORE_PAD0_CSI21_DX0_PAD1_CSI21_DY0.CSI21_DY0_INPUTENABLE
  [4] USBB1_ULPITLL_DAT5_PULLTYPESELECT rw — pullup/down selection for pad usbb1_ulpitll_dat5
    0=pulldown selected; 1=pullup selected
  [3] USBB1_ULPITLL_DAT5_PULLUDENABLE rw — pullup/down enable for pad usbb1_ulpitll_dat5
    0=pullup/down disabled; 1=pullup/down enabled
  [2:0] USBB1_ULPITLL_DAT5_MUXMODE rw — Functional multiplexing selection for pad usbb1_ulpitll_dat5
    0=Select usbb1_ulpitll_dat5; 1=Select dmtimer9_pwm_evt; 2=Select abe_mcbsp3_dx; 3=Select gpio_93; 4=Select usbb1_ulpiphy_dat5; 6=Select hw_dbg29; 7=Select safe_mode
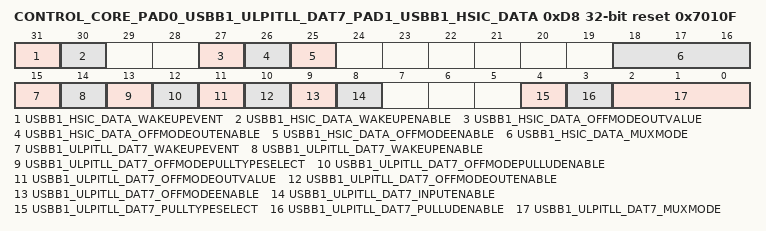
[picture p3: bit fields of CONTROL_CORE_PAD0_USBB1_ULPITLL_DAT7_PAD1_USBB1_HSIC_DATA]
0xD8 CONTROL_CORE_PAD0_USBB1_ULPITLL_DAT7_PAD1_USBB1_HSIC_DATA reset 0x7010F — Register control for Pads usbb1_ulpitll_dat7 and usbb1_hsic_data Access conditions. Read: unrestricted, Write: unrestricted
  [31] USBB1_HSIC_DATA_WAKEUPEVENT ro — Pad_x wake-up event status latched in the IO
    0=USBB1_HSIC_DATA_WAKEUPEVENT_0_r (No wake-up event occurred); 1=USBB1_HSIC_DATA_WAKEUPEVENT_1_r (A wake-up event occurred)
  [30] USBB1_HSIC_DATA_WAKEUPENABLE rw — Input pad wake-up enable (and OFF mode input enable value)
    values as CONTROL_CORE_PAD0_CSI21_DX0_PAD1_CSI21_DY0.CSI21_DY0_WAKEUPENABLE
  [27] USBB1_HSIC_DATA_OFFMODEOUTVALUE rw — OffMode mode output value for pad usbb1_hsic_data
    0=Set value at 0; 1=Set value at 1
  [26] USBB1_HSIC_DATA_OFFMODEOUTENABLE rw — OffMode mode output enable value for pad usbb1_hsic_data. This is an active low signal
    0=Output enable; 1=Output disable
  [25] USBB1_HSIC_DATA_OFFMODEENABLE rw — OffMode mode override control for pad usbb1_hsic_data
    values as CONTROL_CORE_PAD0_CAM_SHUTTER_PAD1_CAM_STROBE.CAM_STROBE_OFFMODEENABLE
  [18:16] USBB1_HSIC_DATA_MUXMODE rw — Functional multiplexing selection for pad usbb1_hsic_data
    0=Select usbb1_hsic_data; 3=Select gpio_96; 7=Select safe_mode
  [15] USBB1_ULPITLL_DAT7_WAKEUPEVENT ro — Pad_x wake-up event status latched in the IO
    0=USBB1_ULPITLL_DAT7_WAKEUPEVENT_0_r (No wake-up event occurred); 1=USBB1_ULPITLL_DAT7_WAKEUPEVENT_1_r (A wake-up event occurred)
  [14] USBB1_ULPITLL_DAT7_WAKEUPENABLE rw — Input pad wake-up enable (and OFF mode input enable value)
    values as CONTROL_CORE_PAD0_CSI21_DX0_PAD1_CSI21_DY0.CSI21_DY0_WAKEUPENABLE
  [13] USBB1_ULPITLL_DAT7_OFFMODEPULLTYPESELECT rw — OffMode mode pullup/down selection for pad usbb1_ulpitll_dat7
    0=Offmode pulldown selected; 1=Offmode pullup selected
  [12] USBB1_ULPITLL_DAT7_OFFMODEPULLUDENABLE rw — OffMode mode pullup/down enable for pad usbb1_ulpitll_dat7
    values as CONTROL_CORE_PAD0_CAM_SHUTTER_PAD1_CAM_STROBE.CAM_STROBE_OFFMODEPULLUDENABLE
  [11] USBB1_ULPITLL_DAT7_OFFMODEOUTVALUE rw — OffMode mode output value for pad usbb1_ulpitll_dat7
    0=Set value at 0; 1=Set value at 1
  [10] USBB1_ULPITLL_DAT7_OFFMODEOUTENABLE rw — OffMode mode output enable value for pad usbb1_ulpitll_dat7. This is an active low signal
    0=Output enable; 1=Output disable
  [9] USBB1_ULPITLL_DAT7_OFFMODEENABLE rw — OffMode mode override control for pad usbb1_ulpitll_dat7
    values as CONTROL_CORE_PAD0_CAM_SHUTTER_PAD1_CAM_STROBE.CAM_STROBE_OFFMODEENABLE
  [8] USBB1_ULPITLL_DAT7_INPUTENABLE rw — Input enable value for pad usbb1_ulpitll_dat7
    values as CONTROL_CORE_PAD0_CSI21_DX0_PAD1_CSI21_DY0.CSI21_DY0_INPUTENABLE
  [4] USBB1_ULPITLL_DAT7_PULLTYPESELECT rw — pullup/down selection for pad usbb1_ulpitll_dat7
    0=pulldown selected; 1=pullup selected
  [3] USBB1_ULPITLL_DAT7_PULLUDENABLE rw — pullup/down enable for pad usbb1_ulpitll_dat7
    0=pullup/down disabled; 1=pullup/down enabled
  [2:0] USBB1_ULPITLL_DAT7_MUXMODE rw — Functional multiplexing selection for pad usbb1_ulpitll_dat7
    0=Select usbb1_ulpitll_dat7; 1=Select dmtimer11_pwm_evt; 2=Select abe_mcbsp3_fsx; 3=Select gpio_95; 4=Select usbb1_ulpiphy_dat7; 5=Select abe_dmic_clk3; 6=Select hw_dbg31; 7=Select safe_mode
